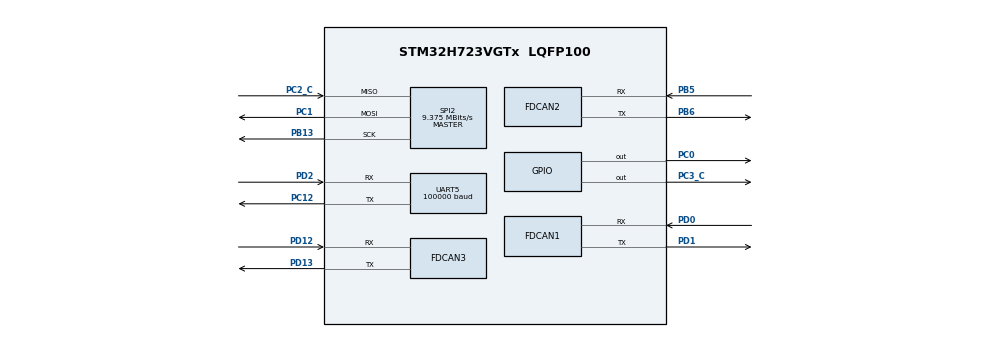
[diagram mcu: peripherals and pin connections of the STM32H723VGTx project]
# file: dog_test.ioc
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CORTEX_M7.default_mode_Activation=1
Dma.Request0=UART5_RX
Dma.UART5_RX.0.Direction=DMA_PERIPH_TO_MEMORY
Dma.UART5_RX.0.EventEnable=DISABLE
Dma.UART5_RX.0.FIFOMode=DMA_FIFOMODE_DISABLE
Dma.UART5_RX.0.Instance=DMA1_Stream0
Dma.UART5_RX.0.MemDataAlignment=DMA_MDATAALIGN_BYTE
Dma.UART5_RX.0.MemInc=DMA_MINC_ENABLE
Dma.UART5_RX.0.Mode=DMA_NORMAL
Dma.UART5_RX.0.PeriphDataAlignment=DMA_PDATAALIGN_BYTE
Dma.UART5_RX.0.PeriphInc=DMA_PINC_DISABLE
Dma.UART5_RX.0.Polarity=HAL_DMAMUX_REQ_GEN_RISING
Dma.UART5_RX.0.Priority=DMA_PRIORITY_LOW
Dma.UART5_RX.0.RequestNumber=1
Dma.UART5_RX.0.SignalID=NONE
Dma.UART5_RX.0.SyncEnable=DISABLE
Dma.UART5_RX.0.SyncPolarity=HAL_DMAMUX_SYNC_NO_EVENT
Dma.UART5_RX.0.SyncRequestNumber=1
Dma.UART5_RX.0.SyncSignalID=NONE
FDCAN1.AutoRetransmission=ENABLE
FDCAN1.CalculateBaudRateNominal=1000000
FDCAN1.CalculateTimeBitNominal=1000
FDCAN1.CalculateTimeQuantumNominal=40.0
FDCAN1.DataPrescaler=9
FDCAN1.DataTimeSeg1=6
FDCAN1.DataTimeSeg2=3
FDCAN1.NominalPrescaler=3
FDCAN1.NominalSyncJumpWidth=6
FDCAN1.NominalTimeSeg1=18
FDCAN1.NominalTimeSeg2=6
FDCAN1.RxFifo0ElmtsNbr=16
FDCAN1.TxFifoQueueElmtsNbr=32
FDCAN2.AutoRetransmission=ENABLE
FDCAN2.CalculateBaudRateNominal=1000000
FDCAN2.CalculateTimeBitNominal=1000
FDCAN2.CalculateTimeQuantumNominal=40.0
FDCAN2.MessageRAMOffset=1280
FDCAN2.NominalPrescaler=3
FDCAN2.NominalSyncJumpWidth=6
FDCAN2.NominalTimeSeg1=18
FDCAN2.NominalTimeSeg2=6
FDCAN2.RxFifo0ElmtsNbr=16
FDCAN2.TxFifoQueueElmtsNbr=32
FDCAN3.AutoRetransmission=ENABLE
FDCAN3.CalculateBaudRateNominal=1000000
FDCAN3.CalculateTimeBitNominal=1000
FDCAN3.CalculateTimeQuantumNominal=40.0
FDCAN3.DataSyncJumpWidth=3
FDCAN3.DataTimeSeg1=11
FDCAN3.DataTimeSeg2=3
FDCAN3.FrameFormat=FDCAN_FRAME_FD_BRS
FDCAN3.MessageRAMOffset=1600
FDCAN3.NominalPrescaler=3
FDCAN3.NominalSyncJumpWidth=6
FDCAN3.NominalTimeSeg1=18
FDCAN3.NominalTimeSeg2=6
FDCAN3.RxFifo0ElmtSize=FDCAN_DATA_BYTES_64
FDCAN3.RxFifo0ElmtsNbr=16
FDCAN3.TxElmtSize=FDCAN_DATA_BYTES_64
FDCAN3.TxEventsNbr=0
FDCAN3.TxFifoQueueElmtsNbr=8
Mcu.Family=STM32H7
Mcu.Name=STM32H723VGTx
Mcu.Package=LQFP100
NVIC.DMA1_Stream0_IRQn=true\:6\:0\:true\:false\:true\:false\:true\:true
NVIC.FDCAN1_IT0_IRQn=true\:0\:0\:false\:false\:true\:true\:true\:true
NVIC.FDCAN2_IT0_IRQn=true\:0\:0\:false\:false\:true\:true\:true\:true
NVIC.FDCAN3_IT0_IRQn=true\:0\:0\:false\:false\:true\:true\:true\:true
NVIC.PriorityGroup=NVIC_PRIORITYGROUP_4
NVIC.TIM6_DAC_IRQn=true\:5\:0\:true\:false\:true\:true\:true\:true
NVIC.UART5_IRQn=true\:6\:0\:true\:false\:true\:true\:true\:true
PB13.Mode=Full_Duplex_Master
PB13.Signal=SPI2_SCK
PB5.Mode=FDCAN_Activate
PB5.Signal=FDCAN2_RX
PB6.Mode=FDCAN_Activate
PB6.Signal=FDCAN2_TX
PC0.PinState=GPIO_PIN_SET
PC0.Signal=GPIO_Output
PC1.Mode=Full_Duplex_Master
PC1.Signal=SPI2_MOSI
PC12.Mode=Asynchronous
PC12.Signal=UART5_TX
PC2_C.Mode=Full_Duplex_Master
PC2_C.Signal=SPI2_MISO
PC3_C.PinState=GPIO_PIN_SET
PC3_C.Signal=GPIO_Output
PD0.Mode=FDCAN_Activate
PD0.Signal=FDCAN1_RX
PD1.Mode=FDCAN_Activate
PD1.Signal=FDCAN1_TX
PD12.Mode=FDCAN_Activate
PD12.Signal=FDCAN3_RX
PD13.Mode=FDCAN_Activate
PD13.Signal=FDCAN3_TX
PD2.Mode=Asynchronous
PD2.Signal=UART5_RX
PH0-OSC_IN.Mode=HSE-External-Oscillator
PH0-OSC_IN.Signal=RCC_OSC_IN
PH1-OSC_OUT.Mode=HSE-External-Oscillator
PH1-OSC_OUT.Signal=RCC_OSC_OUT
ProjectManager.HeapSize=0x200
ProjectManager.StackSize=0x400
ProjectManager.TargetToolchain=CMake
RCC.ADCFreq_Value=48375000
RCC.APB1Freq_Value=50000000
RCC.APB2Freq_Value=50000000
RCC.APB3Freq_Value=50000000
RCC.APB4Freq_Value=50000000
RCC.CortexFreq_Value=100000000
RCC.D1PPRE=RCC_APB3_DIV2
RCC.D2PPRE1=RCC_APB1_DIV2
RCC.D2PPRE2=RCC_APB2_DIV2
RCC.D3PPRE=RCC_APB4_DIV2
RCC.DIVM1=2
RCC.DIVN1=25
RCC.DIVP1=3
RCC.DIVQ1=4
RCC.HCLKFreq_Value=100000000
RCC.HSE_VALUE=24000000
RCC.PLL2FRACN=0
RCC.PLL3FRACN=0
RCC.PLLFRACN=0
RCC.PLLSourceVirtual=RCC_PLLSOURCE_HSE
RCC.SYSCLKFreq_VALUE=100000000
RCC.SYSCLKSource=RCC_SYSCLKSOURCE_PLLCLK
RCC.USBFreq_Value=75000000
SPI2.BaudRatePrescaler=SPI_BAUDRATEPRESCALER_8
SPI2.CLKPhase=SPI_PHASE_2EDGE
SPI2.CLKPolarity=SPI_POLARITY_HIGH
SPI2.CalculateBaudRate=9.375 MBits/s
SPI2.DataSize=SPI_DATASIZE_8BIT
SPI2.Direction=SPI_DIRECTION_2LINES
SPI2.Mode=SPI_MODE_MASTER
SPI2.VirtualType=VM_MASTER
TIM6.AutoReloadPreload=TIM_AUTORELOAD_PRELOAD_ENABLE
TIM6.Period=1999
TIM6.Prescaler=99
UART5.BaudRate=100000
UART5.Mode=MODE_RX
UART5.Parity=PARITY_EVEN
UART5.StopBits=UART_STOPBITS_2
UART5.WordLength=WORDLENGTH_9B
VP_MEMORYMAP_VS_MEMORYMAP.Mode=CurAppReg
VP_TIM6_VS_ClockSourceINT.Mode=Enable_Timer
board=custom

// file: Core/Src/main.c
/* USER CODE BEGIN Header */
/**
  ******************************************************************************
  * @file           : main.c
  * @brief          : Main program body
  ******************************************************************************
  * @attention
  *
  * Copyright (c) 2026 STMicroelectronics.
  * All rights reserved.
  *
  * This software is licensed under terms that can be found in the LICENSE file
  * in the root directory of this software component.
  * If no LICENSE file comes with this software, it is provided AS-IS.
  *
  ******************************************************************************
  */
/* USER CODE END Header */
#include "main.h"
#include "dma.h"
#include "fdcan.h"
#include "memorymap.h"
#include "spi.h"
#include "tim.h"
#include "usart.h"
#include "gpio.h"

/* USER CODE BEGIN Includes */
#include "bsp_can.h"
#include "app_scheduler.h"

/* USER CODE END Includes */

void SystemClock_Config(void);
static void MPU_Config(void);

int main(void)
{

  /* MPU Configuration--------------------------------------------------------*/
  MPU_Config();

  /* MCU Configuration--------------------------------------------------------*/

  /* Reset of all peripherals, Initializes the Flash interface and the Systick. */
  HAL_Init();

  /* Configure the system clock */
  SystemClock_Config();

  /* Initialize all configured peripherals */
  MX_GPIO_Init();
  MX_DMA_Init();
  MX_FDCAN1_Init();
  MX_FDCAN2_Init();
  MX_SPI2_Init();
  MX_TIM6_Init();
  MX_UART5_Init();
  MX_FDCAN3_Init();
  /* USER CODE BEGIN 2 */
  app_can_attach();
  bsp_can_init();
  task_init();
  /* USER CODE END 2 */

  /* Infinite loop */
  while (1)
  {

    /* USER CODE BEGIN 3 */
    task_run();
  }
  /* USER CODE END 3 */
}

void SystemClock_Config(void)
{
  RCC_OscInitTypeDef RCC_OscInitStruct = {0};
  RCC_ClkInitTypeDef RCC_ClkInitStruct = {0};

  /** Supply configuration update enable
  */
  HAL_PWREx_ConfigSupply(PWR_LDO_SUPPLY);

  /** Configure the main internal regulator output voltage
  */
  __HAL_PWR_VOLTAGESCALING_CONFIG(PWR_REGULATOR_VOLTAGE_SCALE2);

  while(!__HAL_PWR_GET_FLAG(PWR_FLAG_VOSRDY)) {}

  /** Initializes the RCC Oscillators according to the specified parameters
  * in the RCC_OscInitTypeDef structure.
  */
  RCC_OscInitStruct.OscillatorType = RCC_OSCILLATORTYPE_HSE;
  RCC_OscInitStruct.HSEState = RCC_HSE_ON;
  RCC_OscInitStruct.PLL.PLLState = RCC_PLL_ON;
  RCC_OscInitStruct.PLL.PLLSource = RCC_PLLSOURCE_HSE;
  RCC_OscInitStruct.PLL.PLLM = 2;
  RCC_OscInitStruct.PLL.PLLN = 25;
  RCC_OscInitStruct.PLL.PLLP = 3;
  RCC_OscInitStruct.PLL.PLLQ = 4;
  RCC_OscInitStruct.PLL.PLLR = 2;
  RCC_OscInitStruct.PLL.PLLRGE = RCC_PLL1VCIRANGE_3;
  RCC_OscInitStruct.PLL.PLLVCOSEL = RCC_PLL1VCOWIDE;
  RCC_OscInitStruct.PLL.PLLFRACN = 0;
  if (HAL_RCC_OscConfig(&RCC_OscInitStruct) != HAL_OK)
  {
    Error_Handler();
  }

  /** Initializes the CPU, AHB and APB buses clocks
  */
  RCC_ClkInitStruct.ClockType = RCC_CLOCKTYPE_HCLK|RCC_CLOCKTYPE_SYSCLK
                              |RCC_CLOCKTYPE_PCLK1|RCC_CLOCKTYPE_PCLK2
                              |RCC_CLOCKTYPE_D3PCLK1|RCC_CLOCKTYPE_D1PCLK1;
  RCC_ClkInitStruct.SYSCLKSource = RCC_SYSCLKSOURCE_PLLCLK;
  RCC_ClkInitStruct.SYSCLKDivider = RCC_SYSCLK_DIV1;
  RCC_ClkInitStruct.AHBCLKDivider = RCC_HCLK_DIV1;
  RCC_ClkInitStruct.APB3CLKDivider = RCC_APB3_DIV2;
  RCC_ClkInitStruct.APB1CLKDivider = RCC_APB1_DIV2;
  RCC_ClkInitStruct.APB2CLKDivider = RCC_APB2_DIV2;
  RCC_ClkInitStruct.APB4CLKDivider = RCC_APB4_DIV2;

  if (HAL_RCC_ClockConfig(&RCC_ClkInitStruct, FLASH_LATENCY_1) != HAL_OK)
  {
    Error_Handler();
  }
}

 /* MPU Configuration */

void MPU_Config(void)
{
  MPU_Region_InitTypeDef MPU_InitStruct = {0};

  /* Disables the MPU */
  HAL_MPU_Disable();

  /** Initializes and configures the Region and the memory to be protected
  */
  MPU_InitStruct.Enable = MPU_REGION_ENABLE;
  MPU_InitStruct.Number = MPU_REGION_NUMBER0;
  MPU_InitStruct.BaseAddress = 0x0;
  MPU_InitStruct.Size = MPU_REGION_SIZE_4GB;
  MPU_InitStruct.SubRegionDisable = 0x87;
  MPU_InitStruct.TypeExtField = MPU_TEX_LEVEL0;
  MPU_InitStruct.AccessPermission = MPU_REGION_NO_ACCESS;
  MPU_InitStruct.DisableExec = MPU_INSTRUCTION_ACCESS_DISABLE;
  MPU_InitStruct.IsShareable = MPU_ACCESS_SHAREABLE;
  MPU_InitStruct.IsCacheable = MPU_ACCESS_NOT_CACHEABLE;
  MPU_InitStruct.IsBufferable = MPU_ACCESS_NOT_BUFFERABLE;

  HAL_MPU_ConfigRegion(&MPU_InitStruct);
  /* Enables the MPU */
  HAL_MPU_Enable(MPU_PRIVILEGED_DEFAULT);

}

void Error_Handler(void)
{
  __disable_irq();
  while (1)
  {
  }
}
